# EFM32HG309F32 register map
File version: 5.8.2
Silicon Labs EFM32HG309F32 Cortex-M MCU
CPU: CM0PLUS r0p1, little endian, no MPU, no FPU, 3 interrupt priority bits
Registers are 32-bit, read-write, reset 0x0 unless marked. A register's access mark holds for its fields unless they carry their own. Offsets are from the block's base; lines under a group give offsets from that group; [hi:lo] are bit positions; {n}, {i} and the like mark numbered series; 'fields as' and 'values as' point back to an identical list; <NAME> marks a mode.

## Memory map
0x40000000 VCMP size 0x400
0x40001000 ACMP0 size 0x400
0x40002000 ADC0 size 0x400
0x40004000 IDAC0 size 0x400
0x40006000 GPIO size 0x1000
0x4000A000 I2C0 size 0x400
0x4000C000 USART0 size 0x400
0x4000C400 USART1 size 0x400
0x40010000 TIMER0 size 0x400
0x40010400 TIMER1 size 0x400
0x40010800 TIMER2 size 0x400
0x40080000 RTC size 0x400
0x40084000 LEUART0 size 0x400
0x40086000 PCNT0 size 0x400
0x40088000 WDOG size 0x400
0x400C0000 MSC size 0x400
0x400C2000 DMA size 0x2000
0x400C4000 USB blocks up to offset 0x3D000
0x400C6000 EMU size 0x400
0x400C8000 CMU size 0x400
0x400CA000 RMU size 0x400
0x400CC000 PRS size 0x400
0x400E0000 AES size 0x400
0xF0040000 MTB size 0x40000

## Interrupts
0 DMA
1 GPIO_EVEN (GPIO)
2 TIMER0
3 ACMP0
4 ADC0
5 I2C0
6 GPIO_ODD (GPIO)
7 TIMER1
8 USART1_RX (USART1)
9 USART1_TX (USART1)
10 LEUART0
11 PCNT0
12 RTC
13 CMU
14 VCMP
15 MSC
16 AES
17 USART0_RX (USART0)
18 USART0_TX (USART0)
19 USB
20 TIMER2

## Further device data
name=Copyright 2019 Silicon Laboratories, Inc., flashBaseAddress=0x00000000, flashSize=0x00008000, flashAccessTypes=rx, sramBaseAddress=0x20000000, sramSize=0x00002000, sramAccessTypes=rwx

## AES
Base 0x400E0000
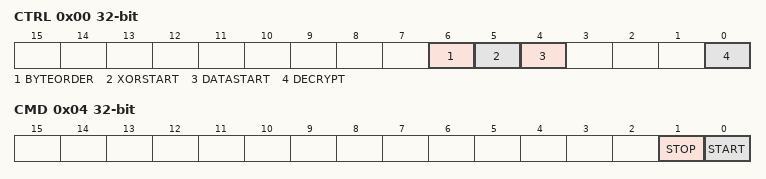
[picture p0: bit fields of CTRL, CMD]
0x00 CTRL — Control Register
  [6] BYTEORDER — Configure byte order in data and key registers
  [5] XORSTART — AES_XORDATA Write Start
  [4] DATASTART — AES_DATA Write Start
  [0] DECRYPT — Decryption/Encryption Mode
0x04 CMD wo — Command Register
  [1] STOP — Encryption/Decryption Stop
  [0] START — Encryption/Decryption Start
0x08 STATUS ro
  [0] RUNNING — AES Running
0x0C IEN — Interrupt Enable Register
  [0] DONE — Encryption/Decryption Done Interrupt Enable
0x10 IF ro — Interrupt Flag Register
  [0] DONE — Encryption/Decryption Done Interrupt Flag
0x14 IFS wo — Interrupt Flag Set Register
  [0] DONE — Encryption/Decryption Done Interrupt Flag Set
0x18 IFC wo — Interrupt Flag Clear Register
  [0] DONE — Encryption/Decryption Done Interrupt Flag Clear
0x1C DATA read-has-side-effects
  [31:0] DATA — Data Access
0x20 XORDATA read-has-side-effects
  [31:0] XORDATA — XOR Data Access
0x30 KEYLA read-has-side-effects — KEY Low Register
  [31:0] KEYLA — Key Low Access A
0x34 KEYLB read-has-side-effects — KEY Low Register
  [31:0] KEYLB — Key Low Access B
0x38 KEYLC read-has-side-effects — KEY Low Register
  [31:0] KEYLC — Key Low Access C
0x3C KEYLD read-has-side-effects — KEY Low Register
  [31:0] KEYLD — Key Low Access D

## Licence text in the file
******************************************************************************* * @version 5.8.2 ******************************************************************************* * # License * Copyright 2019 Silicon Laboratories Inc. www.silabs.com ******************************************************************************* * * SPDX-License-Identifier: Zlib * * The licensor of this software is Silicon Laboratories Inc. * * This software is provided 'as-is', without any express or implied * warranty. In no event will the authors be held liable for any damages * arising from the use of this software. * * Permission is granted to anyone to use this software for any purpose, * including commercial applications, and to alter it and redistribute it * freely, subject to the following restrictions: * * 1. The origin of this software must not be misrepresented; you must not * claim that you wrote the original software. If you use this software * in a product, an acknowledgment in the product documentation would be * appreciated but is not required. * 2. Altered source versions must be plainly marked as such, and must not be * misrepresented as being the original software. * 3. This notice may not be removed or altered from any source distribution. * *******************************************************************************
